# STM32C551 register map
File version: 2.1.0
CPU: CM33 r0p4, little endian, MPU, FPU, 4 interrupt priority bits
Registers are 32-bit, read-write, reset 0x0 unless marked. A register's access mark holds for its fields unless they carry their own. Offsets are from the block's base; [hi:lo] are bit positions; {n}, {i} and the like mark numbered series; 'fields as' and 'values as' point back to an identical list.

## FLASH — FLASH address block description
Base 0x40022000
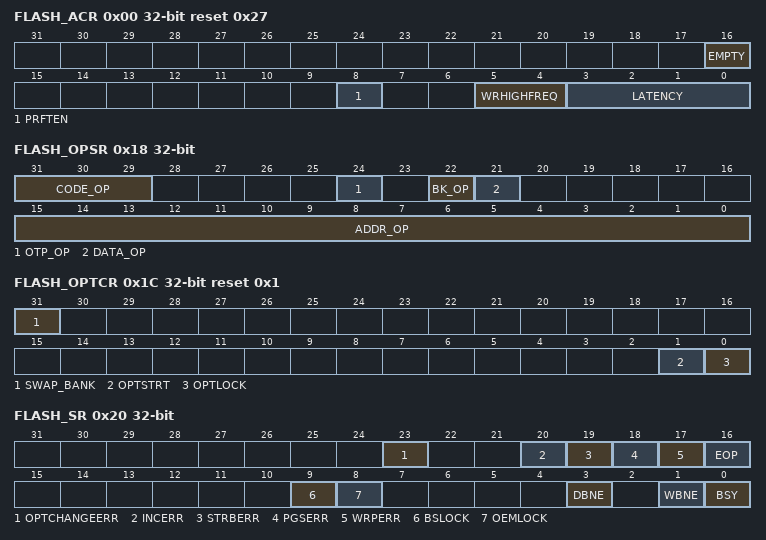
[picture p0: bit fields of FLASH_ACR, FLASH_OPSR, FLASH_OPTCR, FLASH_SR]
0x00 FLASH_ACR reset 0x27 (reset mask 0xFFF0FFFF) — FLASH access control register
  [16] EMPTY — Main flash memory area empty (not reset by system reset)
    0=Boot address in main flash memory area programmed; 1=Boot address in main flash memory area empty
  [8] PRFTEN — Prefetch enable
    0=Prefetch disabled; 1=Prefetch enabled when latency is at least 1 wait-state
  [5:4] WRHIGHFREQ — FLASH signal delay
  [3:0] LATENCY — Read latency
    0=0 wait state; 1=1 wait state; {v}={v} wait states (v=2..15)
0x04 FLASH_KEYR wo — FLASH key register
  [31:0] KEY — Nonvolatile memory configuration access unlock key
0x0C FLASH_OPTKEYR wo — FLASH option key register
  [31:0] OPTKEY — FLASH option-byte control access unlock key
0x18 FLASH_OPSR ro reset not defined — FLASH operation status register
  [31:29] CODE_OP — Flash memory operation code
    0=No FLASH operation ongoing during previous reset; 1=Single write operation interrupted; 3=Page erase operation interrupted; 4=Bank erase operation interrupted; 5=Mass erase operation interrupted; 6=Option change operation interrupted
  [24] OTP_OP — OTP operation interrupted
  [22] BK_OP — Interrupted operation bank
  [21] DATA_OP — FLASH data area operation interrupted
  [15:0] ADDR_OP — Interrupted operation address
0x1C FLASH_OPTCR reset 0x1 (reset mask 0xFFFFFFF) — FLASH option control register
  [31] SWAP_BANK ro — Bank-swapping option configuration bit
    0=Bank1 and bank2 not swapped; 1=Bank1 and bank2 swapped
  [1] OPTSTRT — Option-byte start change option configuration bit
  [0] OPTLOCK — FLASH_OPTCR lock option configuration bit
    0=FLASH_OPTCR register unlocked; 1=FLASH_OPTCR register locked
0x20 FLASH_SR ro (reset mask 0xFFFFFFF0) — FLASH status register
  [23] OPTCHANGEERR — Option-byte change error flag
    0=No option-byte change errors occurred; 1=One or more errors occurred during an option-byte change operation
  [20] INCERR — Inconsistency error flag
    0=No inconsistency error occurred; 1=An inconsistency error occurred
  [19] STRBERR — Strobe error flag
    0=No strobe error occurred; 1=A strobe error occurred
  [18] PGSERR — Programming sequence error flag
    0=No sequence error occurred; 1=A sequence error occurred
  [17] WRPERR — Write protection error flag
    0=No write-protection error occurred; 1=A write-protection error occurred
  [16] EOP — End of operation flag
    0=No operation completed; 1=An operation completed
  [9] BSLOCK
  [8] OEMLOCK
    0=Lock mechanism is not active, progressing to RDP L2_wBS or L2 is irrevocable; 1=Lock mechanism is active, a key exist to regress to RDP L0
  [3] DBNE — Data buffer not empty flag
    0=Data buffer not used; 1=Data buffer used, wait
  [1] WBNE — Write buffer not empty flag
    0=Write buffer empty or full; 1=Write buffer waiting data to complete
  [0] BSY — Busy flag
    0=No programming, erase, or option-byte change operation being executed; 1=Programming, erase, or option byte change operation being executed
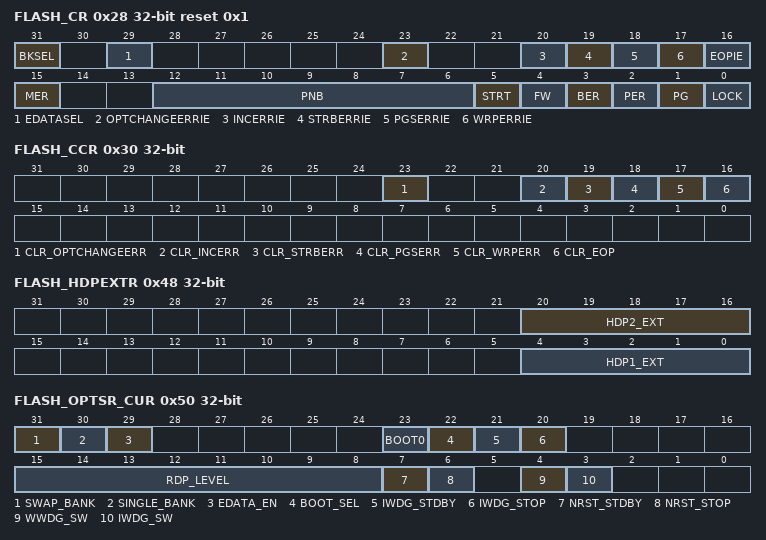
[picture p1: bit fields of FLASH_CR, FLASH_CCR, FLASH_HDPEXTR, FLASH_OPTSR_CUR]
0x28 FLASH_CR reset 0x1 — FLASH control register
  [31] BKSEL — Bank selector bit
    0=Bank1 is selected for bank erase (BER)/page erase (PER)/interrupt enable; 1=Bank2 is selected for BER/PER
  [29] EDATASEL — EDATA erase selector bit
    0=Main FLASH page erase; 1=FLASH data area EDATA page erase
  [23] OPTCHANGEERRIE — Option-byte change error interrupt enable bit
    0=No interrupt is generated when an error occurs during an option-byte change; 1=An interrupt is generated when and error occurs during an option-byte change
  [20] INCERRIE — Inconsistency error interrupt enable bit
    0=No interrupt generated when a inconsistency error occurs; 1=Interrupt generated when a inconsistency error occurs
  [19] STRBERRIE — Strobe error interrupt enable bit
    0=No interrupt generated when a strobe error occurs; 1=Interrupt generated when strobe error occurs
  [18] PGSERRIE — Programming sequence error interrupt enable bit
    0=No interrupt generated when a sequence error occurs; 1=Interrupt generated when sequence error occurs
  [17] WRPERRIE — Write protection error interrupt enable bit
    0=No interrupt generated when a protection error occurs; 1=Interrupt generated when a protection error occurs
  [16] EOPIE — End of operation interrupt control bit
    0=No interrupt generated at the end of operation; 1=Interrupt enabled when at the end of operation
  [15] MER — Mass erase request
    0=Mass erase not requested; 1=Mass erase requested
  [12:6] PNB — Page erase selection number
    0=Page 0 selected; 1=Page 1 selected
  [5] STRT — Erase start control bit
  [4] FW — Write forcing control bit
  [3] BER — Bank-erase request
    0=Bank erase not requested; 1=Bank erase requested
  [2] PER — Page-erase request
    0=Page erase not requested; 1=Page erase requested
  [1] PG — Programming control bit
    0=Programming disabled; 1=Programming enabled
  [0] LOCK — Configuration lock bit
    0=FLASH_CR unlocked; 1=FLASH_CR locked
0x30 FLASH_CCR wo — FLASH clear control register
  [23] CLR_OPTCHANGEERR — OPTCHANGEERR clear bit
  [20] CLR_INCERR — INCERR flag clear bit
  [19] CLR_STRBERR — STRBERR flag clear bit
  [18] CLR_PGSERR — PGSERR flag clear bit
  [17] CLR_WRPERR — WRPERR flag clear bit
  [16] CLR_EOP — EOP flag clear bit
0x3C FLASH_PRIVCFGR — FLASH privilege configuration register
  [1] PRIV — Privilege attribute
    0=Access to registers is always granted; 1=Access to registers is denied in case of unprivileged access
0x48 FLASH_HDPEXTR — FLASH HDP extension register
  [20:16] HDP2_EXT — HDP area extension in 8-Kbyte pages in bank2
  [4:0] HDP1_EXT — HDP area extension in 8-Kbyte pages in bank1
0x50 FLASH_OPTSR_CUR ro reset not defined — FLASH option status register
  [31] SWAP_BANK — Bank-swapping option status bit
    0=Bank1 and bank2 not swapped; 1=Bank1 and bank2 swapped
  [30] SINGLE_BANK — Dual-bank selection option status bit
    0=User flash is split between bank 1 and bank 2; 1=User flash is located in one bank
  [29] EDATA_EN — FLASH data area enable
    0=No FLASH data area (EDATA pages are 128-bit writable); 1=FLASH data area is enabled (EDATA pages are 16/32-bit writable)
  [23] BOOT0 — Boot 0 option bit
    0=BOOT0 = 0; 1=BOOT0 = 1
  [22] BOOT_SEL — Boot 0 source selection
    0=BOOT0 signal is defined by the BOOT0 option bit; 1=BOOT0 signal is defined by BOOT0 pin value (legacy mode)
  [21] IWDG_STDBY — IWDG Standby mode freeze option status bit
    0=IWDG frozen in Standby mode; 1=IWDG keeps running in Standby mode
  [20] IWDG_STOP — IWDG Stop mode freeze option status bit
    0=IWDG frozen in system Stop mode; 1=IWDG keeps running in system Stop mode
  [15:8] RDP_LEVEL — RDP level code (based on Hamming 8,4)
  [7] NRST_STDBY — Core domain Standby entry reset option status bit
    0=A reset is generated when entering Standby mode on core domain; 1=No reset generated when entering Standby mode on core domain
  [6] NRST_STOP — Core domain Stop entry reset option status bit
    0=A reset is generated when entering Stop mode on core domain; 1=No reset generated when entering Stop mode on core domain
  [4] WWDG_SW — WWDG control mode option status bit
    0=WWDG controlled by hardware; 1=WWDG controlled by software
  [3] IWDG_SW — IWDG control mode option status bit
    0=IWDG controlled by hardware; 1=IWDG controlled by software
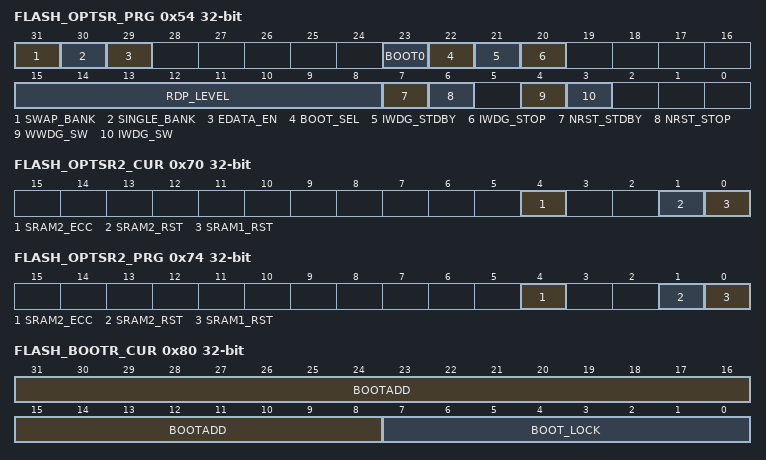
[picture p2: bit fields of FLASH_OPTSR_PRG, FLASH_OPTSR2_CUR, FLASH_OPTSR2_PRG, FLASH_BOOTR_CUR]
0x54 FLASH_OPTSR_PRG reset not defined — FLASH option status register
  [31] SWAP_BANK — Bank-swapping option configuration bit
    0=Bank1 and bank2 not swapped; 1=Bank1 and bank2 swapped
  [30] SINGLE_BANK — Dual-bank option configuration bit
    values as FLASH_OPTSR_CUR.SINGLE_BANK
  [29] EDATA_EN — FLASH data area enable
    0=No FLASH data area; 1=FLASH data area enabled
  [23] BOOT0 — Boot 0 option bit
    0=BOOT0 = 0; 1=BOOT0 = 1
  [22] BOOT_SEL — Boot 0 source configuration
    values as FLASH_OPTSR_CUR.BOOT_SEL
  [21] IWDG_STDBY — IWDG Standby mode freeze option configuration bit
    values as FLASH_OPTSR_CUR.IWDG_STDBY
  [20] IWDG_STOP — IWDG Stop mode freeze option configuration bit
    values as FLASH_OPTSR_CUR.IWDG_STOP
  [15:8] RDP_LEVEL — RDP level code (based on Hamming 8,4)
  [7] NRST_STDBY — Core domain Standby entry reset option configuration bit
    values as FLASH_OPTSR_CUR.NRST_STDBY
  [6] NRST_STOP — Core domain Stop entry reset option configuration bit
    values as FLASH_OPTSR_CUR.NRST_STOP
  [4] WWDG_SW — WWDG control mode option configuration bit
    0=WWDG controlled by hardware; 1=WWDG controlled by software
  [3] IWDG_SW — IWDG control mode option configuration bit
    0=IWDG controlled by hardware; 1=IWDG controlled by software
0x70 FLASH_OPTSR2_CUR ro reset not defined — FLASH option status register 2
  [4] SRAM2_ECC — SRAM2 ECC detection and correction disable
    0=SRAM2 ECC check enabled; 1=SRAM2 ECC check disabled
  [1] SRAM2_RST — SRAM2 erase when system reset
    0=SRAM2 erased when a system reset occurs; 1=SRAM2 not erased when a system reset occurs
  [0] SRAM1_RST — SRAM1 erase upon system reset
    0=SRAM1 erased when a system reset occurs; 1=SRAM1 not erased when a system reset occurs
0x74 FLASH_OPTSR2_PRG reset not defined — FLASH option status register 2
  fields as FLASH_OPTSR2_CUR
0x80 FLASH_BOOTR_CUR ro reset not defined — FLASH unique boot entry register
  [31:8] BOOTADD — Unique boot-entry address
  [7:0] BOOT_LOCK — BOOT0, BOOT_SEL, SWAP_BANK, and BOOTADD option settings lock
    195=BOOT0, BOOT_SEL, SWAP_BANK, and BOOTADD can still be modified following their individual rules; 180=BOOT0, BOOT_SEL, SWAP_BANK, and BOOTADD are frozen
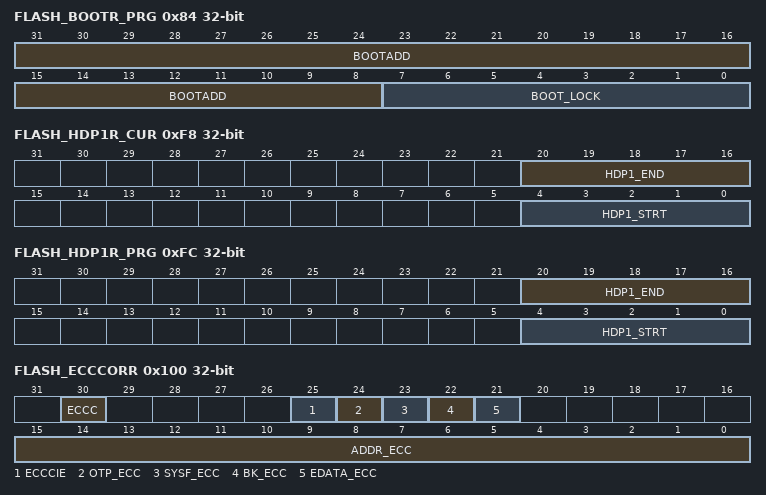
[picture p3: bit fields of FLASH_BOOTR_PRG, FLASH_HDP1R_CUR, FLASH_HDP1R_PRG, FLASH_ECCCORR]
0x84 FLASH_BOOTR_PRG reset not defined — FLASH unique boot entry address
  [31:8] BOOTADD — Unique boot entry address
  [7:0] BOOT_LOCK — BOOT0, BOOT_SEL, SWAP_BANK, and BOOTADD option settings lock
    values as FLASH_BOOTR_CUR.BOOT_LOCK
0x90 FLASH_OTPBLR_CUR ro (reset mask 0xFF000000) — FLASH OTP block lock
  [23:0] LOCKBL — OTP block lock
0x94 FLASH_OTPBLR_PRG (reset mask 0xFF000000) — FLASH OTP block lock
  [23:0] LOCKBL — OTP block lock
0x98 FLASH_BL_COM_CFG_CUR ro reset not defined — FLASH bootloader interface selection
  [31:0] BL_COM_CFG — Bootloader interface selection/configuration
0x9C FLASH_BL_COM_CFG_PRG reset not defined — FLASH bootloader interface selection
  [31:0] BL_COM_CFG — Bootloader interface selection/configuration
0xA4 FLASH_OEMKEYR1_PRG wo reset not defined — FLASH OEM key register 1
  [31:0] OEMKEY — Least significants bytes of OEMKEY
0xAC FLASH_OEMKEYR2_PRG wo reset not defined — FLASH OEM key register 2
  [31:0] OEMKEY — Mid-least significants bytes of OEMKEY
0xB4 FLASH_OEMKEYR3_PRG wo reset not defined — FLASH OEM key register 3
  [31:0] OEMKEY — Mid-most significants bytes of OEMKEY
0xBC FLASH_OEMKEYR4_PRG wo reset not defined — FLASH OEM key register 4
  [31:0] OEMKEY — Most significants bytes of OEMKEY
0xC4 FLASH_BSKEYR_PRG wo reset not defined — FLASH boundary scan key register
  [31:0] BSKEY — Boundary scan key
0xE8 FLASH_WRP1R_CUR ro reset not defined — FLASH write page protection for bank1
  [31:0] WRPSG1 — Bank1 page protection option status byte
    0=Write protected; 1=Not write protected
0xEC FLASH_WRP1R_PRG reset not defined — FLASH write-page protection for bank1
  fields as FLASH_WRP1R_CUR
0xF8 FLASH_HDP1R_CUR ro reset not defined — FLASH HDP bank1 register
  [20:16] HDP1_END — HDPL barrier end set in number of 8-Kbyte pages
  [4:0] HDP1_STRT — HDPL barrier start set in number of 8-Kbyte pages
0xFC FLASH_HDP1R_PRG reset not defined — FLASH HDP bank1 register
  [20:16] HDP1_END — Bank 1 HDPL barrier end set in number of 8-Kbyte pages
  [4:0] HDP1_STRT — Bank 1 HDPL barrier start set in number of 8-Kbyte pages
0x100 FLASH_ECCCORR — FLASH ECC correction register
  [30] ECCC — ECC correction
  [25] ECCCIE — ECC single-correction error interrupt enable bit
    0=No interrupt generated when an ECC single-correction error occurs; 1=Interrupt generated when an ECC single-correction error occurs
  [24] OTP_ECC ro — OTP ECC error bit
  [23] SYSF_ECC ro — ECC flag for corrected ECC error in system FLASH
  [22] BK_ECC ro — ECC bank flag for corrected ECC error
  [21] EDATA_ECC ro — ECC fail for corrected ECC error in FLASH data area
  [15:0] ADDR_ECC ro — ECC error address
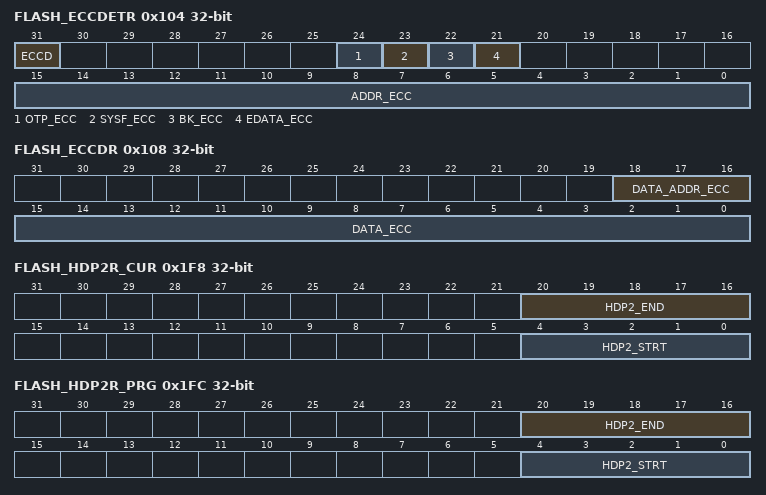
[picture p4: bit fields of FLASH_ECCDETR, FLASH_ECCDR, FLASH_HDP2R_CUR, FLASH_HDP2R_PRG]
0x104 FLASH_ECCDETR — FLASH ECC detection register
  [31] ECCD — ECC detection set by hardware when two ECC errors have been detected
  [24] OTP_ECC ro — OTP ECC error bit
  [23] SYSF_ECC ro — ECC fail for double ECC error in system flash memory
  [22] BK_ECC ro — ECC fail bank for double ECC Error
  [21] EDATA_ECC ro — ECC fail for double ECC error in FLASH data area
  [15:0] ADDR_ECC ro — ECC error address
0x108 FLASH_ECCDR ro — FLASH ECC data
  [18:16] DATA_ADDR_ECC — DATA ECC error address
    0=Double error on first 16-bit data or first 32-bit data accessed on the FLASH line; 1=Double error on second 16-bit data accessed on the FLASH line; 2=Double error on third 16-bit data or second 32-bit data accessed on the FLASH line; 3=Double error on fourth 16-bit data accessed on the FLASH line; 4=Double error on fifth 16-bit data or third 32-bit data accessed on the FLASH line; 5=Double error on sixth 16-bit data
  [15:0] DATA_ECC — ECC error data
0x1E8 FLASH_WRP2R_CUR ro reset not defined — FLASH write page protection for bank2
  [31:0] WRPSG2 — Bank2 page protection option status byte
    0=Write protected; 1=Not write protected
0x1EC FLASH_WRP2R_PRG reset not defined — FLASH write page protection for bank2
  [31:0] WRPSG2 — Bank2 page protection option status byte
    0=write protected;; 1=not write protected
0x1F8 FLASH_HDP2R_CUR ro reset not defined — FLASH HDP bank2 register
  [20:16] HDP2_END — Bank 2 HDPL barrier end set in number of 8-Kbyte pages
  [4:0] HDP2_STRT — Bank 2 HDPL barrier start set in number of 8-Kbyte pages
0x1FC FLASH_HDP2R_PRG reset not defined — FLASH HDP bank2 register
  fields as FLASH_HDP2R_CUR
